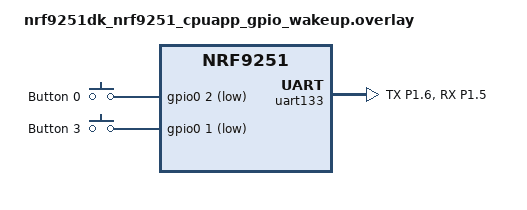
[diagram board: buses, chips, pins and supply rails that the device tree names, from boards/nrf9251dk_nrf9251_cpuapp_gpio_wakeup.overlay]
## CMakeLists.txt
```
#
# Copyright (c) 2026 Nordic Semiconductor ASA
#
# SPDX-License-Identifier: LicenseRef-Nordic-5-Clause
#

cmake_minimum_required(VERSION 3.20.0)
find_package(Zephyr REQUIRED HINTS $ENV{ZEPHYR_BASE})
project(nrf_system_off)

target_sources(app PRIVATE src/main.c)
if(CONFIG_SAMPLE_STATE_RETENTION)
  target_sources(app PRIVATE src/retained.c)
endif()
```

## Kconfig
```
#
# Copyright (c) 2026 Nordic Semiconductor ASA
#
# SPDX-License-Identifier: LicenseRef-Nordic-5-Clause
#

mainmenu "System off sample"

config SAMPLE_STATE_RETENTION
	bool "State retention in system off"
	select RETAINED_MEM
	help
	  Enable state retention in system off using retained memory driver.

config SAMPLE_GPIO_WAKEUP
	bool "Wake up from system off using a button"
	default y
	help
	  Enable wakeup from system off by pressing Button 0.

config SAMPLE_GRTC_WAKEUP
	bool "Wake up from system off using GRTC"
	help
	  Enable wakeup from system off using General Real-Time Counter (GRTC).

source "Kconfig.zephyr"
```

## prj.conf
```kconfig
#
# Copyright (c) 2026 Nordic Semiconductor ASA
#
# SPDX-License-Identifier: LicenseRef-Nordic-5-Clause
#

CONFIG_PM=y
CONFIG_PM_DEVICE=y
CONFIG_GPIO=y
CONFIG_CRC=y
CONFIG_POWEROFF=y
CONFIG_HWINFO=y
```

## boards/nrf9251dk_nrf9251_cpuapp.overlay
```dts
/*
 * Copyright (c) 2026 Nordic Semiconductor ASA
 *
 * SPDX-License-Identifier: LicenseRef-Nordic-5-Clause
 */

#include <samples/cellular/nrf92_no_bootloader_partitions.dtsi>

/ {
	cpuapp_tcm_sram_ret: cpuapp_tcm_sram@22006f00 {
		compatible = "zephyr,memory-region", "mmio-sram";
		reg = <0x22006f00 DT_SIZE_K(4)>;
		zephyr,memory-region = "RetainedMem";
		status = "okay";

		retainedmem0: retainedmem {
			compatible = "zephyr,retained-ram";
			status = "okay";
		};
	};

	aliases {
		retainedmemdevice = &retainedmem0;
	};
};

&cpuapp_tcm_region {
	/* Shrink the app TCM region to make room for the retained memory region. */
	reg = <0x0 0x6f00>;
};
```

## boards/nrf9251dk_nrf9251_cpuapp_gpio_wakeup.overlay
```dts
/*
 * Copyright (c) 2026 Nordic Semiconductor ASA
 *
 * SPDX-License-Identifier: LicenseRef-Nordic-5-Clause
 */

/* Test requires loopback
 * from RXD0 (P1.05) to P0.02
 */

/ {
	/*
	 * Swap button0 with button3
	 * (P0.01 is already used in CI setup for other purposes).
	 */
	buttons {
		compatible = "gpio-keys";

		button0: button_0 {
			gpios = <&gpio0 2 (GPIO_PULL_UP | GPIO_ACTIVE_LOW)>;
			label = "Button 0";
		};

		button3: button_3 {
			gpios = <&gpio0 1 (GPIO_PULL_UP | GPIO_ACTIVE_LOW)>;
			label = "Button 3";
		};
	};
};

/* Disable UART flow-control. This is just to unlock debugger chip.
 * When debugger chip receives data from PC it passes data to nrf9251 P1.05.
 * Nrf9251 UART peripheral ignores transmission.
 * External GPIO loopback shorts P1.05 with P0.02 (button_0).
 * UART signal is treated as button press and release.
 */
&pinctrl {
	uart133_default_alt: uart133_default_alt {
		group1 {
			psels = <NRF_PSEL(UART_TX, 1, 6)>;
		};

		group3 {
			psels = <NRF_PSEL(UART_RX, 1, 5)>;
			bias-pull-up;
		};
	};

	uart133_sleep_alt: uart133_sleep_alt {
		group1 {
			psels = <NRF_PSEL(UART_TX, 1, 6)>,
				<NRF_PSEL(UART_RX, 1, 5)>;
			low-power-enable;
		};
	};
};

&uart133 {
	pinctrl-0 = <&uart133_default_alt>;
	pinctrl-1 = <&uart133_sleep_alt>;
	pinctrl-names = "default", "sleep";
	/delete-property/ hw-flow-control;
};
```

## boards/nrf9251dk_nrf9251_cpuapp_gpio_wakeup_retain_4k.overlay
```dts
#include "nrf9251dk_nrf9251_cpuapp_gpio_wakeup.overlay"
#include "nrf9251dk_nrf9251_cpuapp.overlay"
```

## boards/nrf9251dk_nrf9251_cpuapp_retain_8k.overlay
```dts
/*
 * Copyright (c) 2026 Nordic Semiconductor ASA
 *
 * SPDX-License-Identifier: LicenseRef-Nordic-5-Clause
 */

/ {
	cpuapp_tcm_sram_ret: cpuapp_tcm_sram@22005f00 {
		compatible = "zephyr,memory-region", "mmio-sram";
		reg = <0x22005f00 DT_SIZE_K(8)>;
		zephyr,memory-region = "RetainedMem";
		status = "okay";

		retainedmem0: retainedmem {
			compatible = "zephyr,retained-ram";
			status = "okay";
		};
	};

	aliases {
		retainedmemdevice = &retainedmem0;
	};
};

&cpuapp_tcm_region {
	/* Shrink the app TCM region to make room for the retained memory region. */
	reg = <0x0 0x5f00>;
};
```

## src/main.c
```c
/*
 * Copyright (c) 2026 Nordic Semiconductor ASA
 *
 * SPDX-License-Identifier: LicenseRef-Nordic-5-Clause
 */

#include <stdio.h>

#include <hal/nrf_grtc.h>
#include <zephyr/kernel.h>
#include <zephyr/drivers/gpio.h>
#include <zephyr/drivers/hwinfo.h>
#include <zephyr/pm/device.h>
#include <zephyr/pm/device_runtime.h>
#include <zephyr/sys/poweroff.h>

#include <modem/nrf_modem_lib.h>

#include "retained.h"

/* System OFF time in seconds when GRTC wakeup is enabled */
#define SYSTEM_OFF_TIME_S 2

#define NON_WAKEUP_RESET_REASON (RESET_PIN | RESET_SOFTWARE | RESET_POR | RESET_DEBUG)

#define GRTC_NODE DT_NODELABEL(grtc)
#define GRTC_CC_CHANNEL DT_PROP_BY_IDX(GRTC_NODE, owned_channels, 0)

static const struct device *const console = DEVICE_DT_GET(DT_CHOSEN(zephyr_console));

#if defined(CONFIG_SAMPLE_GPIO_WAKEUP)
static const struct gpio_dt_spec button0 = GPIO_DT_SPEC_GET(DT_NODELABEL(button0), gpios);
#endif

static int print_reset_cause(uint32_t reset_cause)
{
	int ret;
	uint32_t supported;

	ret = hwinfo_get_supported_reset_cause(&supported);

	if (ret || !(reset_cause & supported)) {
		return -ENOTSUP;
	}

	if (reset_cause & RESET_CLOCK) {
		printf("Wakeup from System OFF by GRTC\n");
	} else if (reset_cause & RESET_LOW_POWER_WAKE) {
		printf("Wakeup from System OFF by GPIO\n");
	} else  {
		printf("Other wakeup cause 0x%08X\n", reset_cause);
	}

	return 0;
}

int main(void)
{
	int ret;
	uint32_t reset_cause;

	if (!device_is_ready(console)) {
		printf("%s: device not ready.\n", console->name);
		return -1;
	}

	printf("\nSystem off sample\n");

	hwinfo_get_reset_cause(&reset_cause);
	ret = print_reset_cause(reset_cause);
	if (ret < 0) {
		printf("Reset cause not supported\n");
		return ret;
	}

	ret = nrf_modem_lib_init();
	if (ret < 0) {
		printf("Failed to initialize modem library: %d\n", ret);
		return ret;
	}

	if (IS_ENABLED(CONFIG_SAMPLE_STATE_RETENTION)) {
		bool retained_ok = retained_validate();

		if (reset_cause & NON_WAKEUP_RESET_REASON) {
			retained.boots = 0;
			retained.off_count = 0;
			retained.uptime_sum = 0;
			retained.uptime_latest = 0;
			retained_ok = true;
		}
		/* Increment for this boot attempt and update */
		retained.boots += 1;
		retained_update();

		printf("Retained data: %s\n", retained_ok ? "valid" : "INVALID");
		printf("Boot count: %u\n", retained.boots);
		printf("Off count: %u\n", retained.off_count);
		printf("Active ticks: %llu\n", retained.uptime_sum);
	} else {
		printf("State retention disabled\n");
	}

	ret = nrf_modem_lib_shutdown();
	if (ret < 0) {
		printf("Failed to shutdown modem library: %d\n", ret);
		return ret;
	}

#if defined(CONFIG_SAMPLE_GRTC_WAKEUP)
	printf("Entering System OFF; wait %u seconds to restart\n", SYSTEM_OFF_TIME_S);
	nrf_grtc_sys_counter_cc_add_set(NRF_GRTC, GRTC_CC_CHANNEL, SYSTEM_OFF_TIME_S * USEC_PER_SEC,
					NRF_GRTC_CC_ADD_REFERENCE_SYSCOUNTER);
#else
	nrf_grtc_sys_counter_compare_event_disable(NRF_GRTC, GRTC_CC_CHANNEL);
#endif /* CONFIG_SAMPLE_GRTC_WAKEUP */

#if defined(CONFIG_SAMPLE_GPIO_WAKEUP)
	/* Configure button 0 as input, interrupt as level active to allow wakeup */
	ret = gpio_pin_configure_dt(&button0, GPIO_INPUT);
	if (ret < 0) {
		printf("Could not configure Button 0 GPIO (%d)\n", ret);
		return ret;
	}

	ret = gpio_pin_interrupt_configure_dt(&button0, GPIO_INT_LEVEL_ACTIVE);
	if (ret < 0) {
		printf("Could not configure Button 0 GPIO interrupt (%d)\n", ret);
		return ret;
	}

	printf("Entering System OFF; press Button 0 to restart\n");
#endif /* CONFIG_SAMPLE_GPIO_WAKEUP */

	/* Suspend console */
	do {
		enum pm_device_state state;

		ret = pm_device_state_get(console, &state);
		if (ret) {
			return ret;
		}

		if (state != PM_DEVICE_STATE_ACTIVE) {
			break;
		}

		pm_device_runtime_put(console);
	} while (1);

	if (IS_ENABLED(CONFIG_SAMPLE_STATE_RETENTION)) {
		/* Update the retained state */
		retained.off_count += 1;
		retained_update();
	}

	hwinfo_clear_reset_cause();

	sys_poweroff();

	return 0;
}
```

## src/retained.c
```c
/*
 * Copyright (c) 2026 Nordic Semiconductor ASA
 *
 * SPDX-License-Identifier: LicenseRef-Nordic-5-Clause
 */

#include <zephyr/kernel.h>
#include <zephyr/devicetree.h>
#include <zephyr/drivers/retained_mem.h>
#include <zephyr/sys/byteorder.h>
#include <zephyr/sys/crc.h>

#include "retained.h"

#if DT_NODE_HAS_STATUS_OKAY(DT_ALIAS(retainedmemdevice))
const static struct device *retained_mem_device = DEVICE_DT_GET(DT_ALIAS(retainedmemdevice));
#else
#error "retained_mem region not defined"
#endif

struct retained_data retained;

#define RETAINED_CRC_OFFSET offsetof(struct retained_data, crc)
#define RETAINED_CHECKED_SIZE (RETAINED_CRC_OFFSET + sizeof(retained.crc))

bool retained_validate(void)
{
	int ret;

	ret = retained_mem_read(retained_mem_device, 0, (uint8_t *)&retained, sizeof(retained));
	__ASSERT_NO_MSG(ret == 0);

	/* The residue of a CRC is what you get from the CRC over the
	 * message catenated with its CRC.  This is the post-final-xor
	 * residue for CRC-32 (CRC-32/ISO-HDLC) which Zephyr calls
	 * crc32_ieee.
	 */
	const uint32_t residue = 0x2144df1c;
	uint32_t crc = crc32_ieee((const uint8_t *)&retained,
				  RETAINED_CHECKED_SIZE);
	bool valid = (crc == residue);

	/* If the CRC isn't valid, reset the retained data. */
	if (!valid) {
		memset(&retained, 0, sizeof(retained));
	}

	/* Reset to accrue runtime from this session. */
	retained.uptime_latest = 0;

	return valid;
}

void retained_update(void)
{
	int ret;

	uint64_t now = k_uptime_ticks();

	retained.uptime_sum += (now - retained.uptime_latest);
	retained.uptime_latest = now;

	uint32_t crc = crc32_ieee((const uint8_t *)&retained,
				  RETAINED_CRC_OFFSET);

	retained.crc = sys_cpu_to_le32(crc);

	ret = retained_mem_write(retained_mem_device, 0, (uint8_t *)&retained, sizeof(retained));
	__ASSERT_NO_MSG(ret == 0);
}
```

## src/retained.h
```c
/*
 * Copyright (c) 2026 Nordic Semiconductor ASA
 *
 * SPDX-License-Identifier: LicenseRef-Nordic-5-Clause
 */

#ifndef RETAINED_H_
#define RETAINED_H_

/* Example of validatable retained data. */
struct retained_data {
	/* The uptime from the current session the last time the
	 * retained data was updated.
	 */
	uint64_t uptime_latest;

	/* Cumulative uptime from all previous sessions up through
	 * uptime_latest of this session.
	 */
	uint64_t uptime_sum;

	/* Number of times the application has started. */
	uint32_t boots;

	/* Number of times the application has gone into system off. */
	uint32_t off_count;

	/* CRC used to validate the retained data.  This must be
	 * stored little-endian, and covers everything up to but not
	 * including this field.
	 */
	uint32_t crc;
};

/* For simplicity in the sample just allow anybody to see and
 * manipulate the retained state.
 */
extern struct retained_data retained;

/* Check whether the retained data is valid, and if not reset it.
 *
 * @return true if and only if the data was valid and reflects state
 * from previous sessions.
 */
bool retained_validate(void);

/* Update any generic retained state and recalculate its checksum so
 * subsequent boots can verify the retained state.
 */
void retained_update(void);

#endif /* RETAINED_H_ */
```
